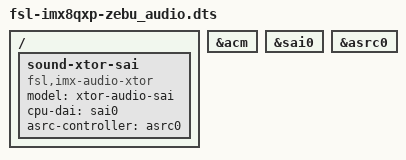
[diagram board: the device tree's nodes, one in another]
/*
 * Copyright (C) 2016 Freescale Semiconductor, Inc.
 * Copyright 2017 NXP
 *
 * This program is free software; you can redistribute it and/or
 * modify it under the terms of the GNU General Public License
 * as published by the Free Software Foundation; either version 2
 * of the License, or (at your option) any later version.
 *
 * This program is distributed in the hope that it will be useful,
 * but WITHOUT ANY WARRANTY; without even the implied warranty of
 * MERCHANTABILITY or FITNESS FOR A PARTICULAR PURPOSE.  See the
 * GNU General Public License for more details.
 */

#include "fsl-imx8qxp-zebu.dts"

/ {
	sound-xtor-sai {
		compatible = "fsl,imx-audio-xtor";
		model = "xtor-audio-sai";
		cpu-dai = <&sai0>;
		asrc-controller = <&asrc0>;
	};
};

&acm {
	status = "okay";
};

&sai0 {
	status = "okay";
};

&asrc0 {
	status = "okay";
};

